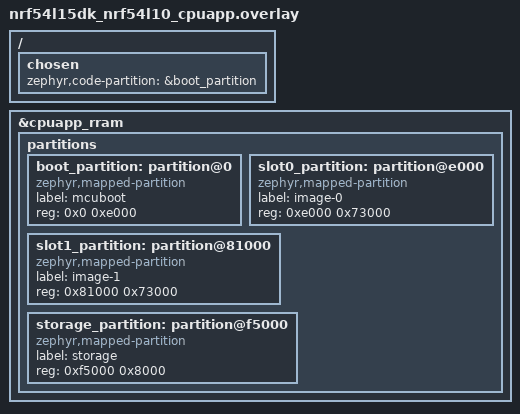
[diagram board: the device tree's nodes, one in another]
/*
 * Copyright (c) 2026 Nordic Semiconductor ASA
 *
 * SPDX-License-Identifier: LicenseRef-Nordic-5-Clause
 */

/ {
	chosen {
		zephyr,code-partition = &boot_partition;
	};
};

/delete-node/ &boot_partition;
/delete-node/ &slot0_partition;
/delete-node/ &slot1_partition;
/delete-node/ &storage_partition;

&cpuapp_rram {
	partitions {
		boot_partition: partition@0 {
			compatible = "zephyr,mapped-partition";
			label = "mcuboot";
			reg = <0x0 0xe000>;
		};

		slot0_partition: partition@e000 {
			compatible = "zephyr,mapped-partition";
			label = "image-0";
			reg = <0xe000 0x73000>;
		};

		slot1_partition: partition@81000 {
			compatible = "zephyr,mapped-partition";
			label = "image-1";
			reg = <0x81000 0x73000>;
		};

		storage_partition: partition@f5000 {
			compatible = "zephyr,mapped-partition";
			label = "storage";
			reg = <0xf5000 0x8000>;
		};
	};
};
